# c75_DMC register map
Vendor: Texas Instruments
Peripheral module from a debugger description file (folder C75).
Registers are 64-bit, access per field, reset 0x0 unless marked. A register's access mark holds for its fields unless they carry their own. Offsets are as the file gives them; lines under a group give offsets from that group; [hi:lo] are bit positions; {n}, {i} and the like mark numbered series; 'fields as' and 'values as' point back to an identical list; <NAME> marks a mode.

## DMC(L1D) — Data Memory Controller
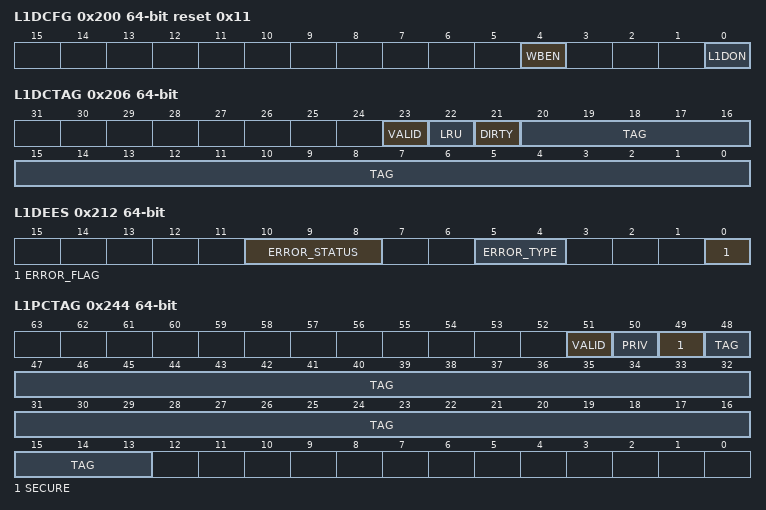
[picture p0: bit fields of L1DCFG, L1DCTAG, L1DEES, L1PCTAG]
0x200 L1DCFG reset 0x11 — L1D Cache Configuration Register
  [4] WBEN rw — Writeback enable
  [0] L1DON rw — Turns the cache on or off
0x202 L1DWB — L1D Global Writeback Register
  [0] WB rw — Controls the Global Writeback of L1D Cache
0x203 L1DWBINV — L1D Global Writeback Invalidate Register
  [0] WBINV rw — Writeback and invalidate all lines L1D Cache
0x204 L1DINV — L1D Invalidate Register
  [0] INV rw — Controls the Global Invalidation of L1D Cache
0x206 L1DCTAG ro — L1D Cache tag View
  [23] VALID — Valid bit
  [22] LRU — LRU bit
  [21] DIRTY — LRU bit
  [20:0] TAG
0x211 L1DEEA ro — L1D Error Event Address
  [35:0] EADDR — Transaction address for which error was detected
0x212 L1DEES ro — L1D Error Event Status
  [10:8] ERROR_STATUS
  [5:4] ERROR_TYPE — Type of Error - Address outside implemented SRAM, SRAM under cache; LUT Base address outside implemented SRAM
  [0] ERROR_FLAG — Indicates that an address error occurred and has not been cleared yet. Clear occurs on a write to L1DEER
0x213 L1DEER — L1D Error Event Reset
  [0] ERROR_RESET wo — Clear error in L1DEES
0x244 L1PCTAG ro — L1P Cache Tag View
  [51] VALID — Valid bit
  [50] PRIV — Privilege
  [49] SECURE — Secure bit
  [48:13] TAG — Cache tag
